# AT32F437 register map
Vendor: Keil; Series: AT32F437; File version: 1.0
CPU: CM4 r0p1, little endian, no MPU, FPU, 4 interrupt priority bits
Registers are 32-bit, read-write, reset 0x0 unless marked. A register's access mark holds for its fields unless they carry their own. Offsets are from the block's base; [hi:lo] are bit positions.

## SPI1 — Serial peripheral interface
Base 0x40013000
Same registers: SPI2 0x40003800, SPI3 0x40003C00, SPI4 0x40013400, I2S2_EXT 0x40017800, I2S3_EXT 0x40017C00
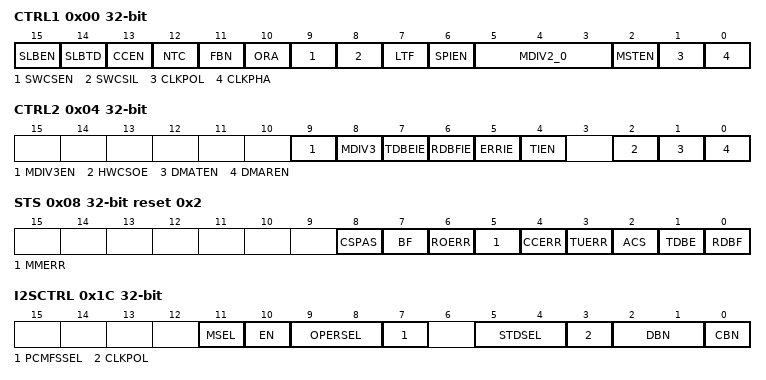
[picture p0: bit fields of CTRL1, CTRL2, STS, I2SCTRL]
0x00 CTRL1 — control register 1
  [15] SLBEN — Single line bidirectional half-duplex enable
    on read: 0=Disabled (Single line bidirectional half-duplex is disabled); 1=Enabled (Single line bidirectional half-duplex is enabled) | on write: 0=Disable (Single line bidirectional half-duplex disable); 1=Enable (Single line bidirectional half-duplex enable)
  [14] SLBTD — Single line bidirectional half-duplex transmission direction
    0=Receive-only mode; 1=Transmit-only mode
  [13] CCEN — CRC calculation enable
    on read: 0=Disabled (CRC calculation is disabled); 1=Enabled (CRC calculation is enabled) | on write: 0=Disable (CRC calculation disable); 1=Enable (CRC calculation enable)
  [12] NTC — Next transmission CRC
    0=Normal (Next transmitted data is the normal value); 1=CRC (Next transmitted data is CRC value)
  [11] FBN — frame bit num
    0=bit8 (8-bit data frame); 1=bit16 (16-bit data frame)
  [10] ORA — Only receive active
    0=RxTx (Transmission and reception); 1=Receive-only mode
  [9] SWCSEN — Software CS enable
    on read: 0=Disabled (Software CS is disabled); 1=Enabled (Software CS is enabled) | on write: 0=Disable (Software CS disable); 1=Enable (Software CS enable)
  [8] SWCSIL — Software CS internal level
    0=Low (Low level); 1=High level
  [7] LTF — LSB transmit first
    0=MSB (Most significant bit first); 1=LSB (Least significant bit first)
  [6] SPIEN — SPI enable
    on read: 0=Disabled (SPI is disabled); 1=Enabled (SPI is enabled) | on write: 0=Disable (SPI disable); 1=Enable (SPI enable)
  [5:3] MDIV2_0 — MDIV[2:0] — master clock frequency division bits 2-0. Combined with MDIV3 (in CTRL2) to form MDIV[3:0]. 0: Divided by 2, 1: Divided by 4, 2: Divided by 8, 3: Divided by 16, 4: Divided by 32, 5: Divided by 64, 6: Divided by 128, 7: Divided by 256, 8: Divided by 512, 9: Divided by 1024
  [2] MSTEN — Master enable
    0=Slave (Master is disabled (Slave)"); 1=Master is enabled"
  [1] CLKPOL — Clock polarity
    0=Low (Low level); 1=High level
  [0] CLKPHA — Clock phase
    0=First (Data capture starts from the first clock edge); 1=Second (Data capture starts from the second clock edge)
0x04 CTRL2 — control register 2
  [9] MDIV3EN — Master clock frequency3 division enable
    0=Disabled; 1=Enabled. MDIV is ignored and SPI clock set to PCLK/3
  [8] MDIV3 — MDIV[3] — master clock frequency division bit 3. Combined with MDIV2_0 (in CTRL1) to form MDIV[3:0]. 0: Divided by 2, 1: Divided by 4, 2: Divided by 8, 3: Divided by 16, 4: Divided by 32, 5: Divided by 64, 6: Divided by 128, 7: Divided by 256, 8: Divided by 512, 9: Divided by 1024
  [7] TDBEIE — Transmit data buffer empty interrupt enable
    on read: 0=Disabled (Transmit data buffer empty interrupt is disabled); 1=Enabled (Transmit data buffer empty interrupt is enabled) | on write: 0=Disable (Transmit data buffer empty interrupt disable); 1=Enable (Transmit data buffer empty interrupt enable)
  [6] RDBFIE — Receive data buffer full interrupt enable
    on read: 0=Disabled (Receive data buffer full interrupt is disabled); 1=Enabled (Receive data buffer full interrupt is enabled) | on write: 0=Disable (Receive data buffer full interrupt disable); 1=Enable (Receive data buffer full interrupt enable)
  [5] ERRIE — Error interrupt enable
    on read: 0=Disabled (Error interrupt is disabled); 1=Enabled (Error interrupt is enabled) | on write: 0=Disable (Error interrupt disable); 1=Enable (Error interrupt enable)
  [4] TIEN — TI mode enable
    0=Disabled (TI mode is disabled (Motorola mode)); 1=Enabled (TI mode is enabled (TI mode))
  [2] HWCSOE — Hardware CS output enable
    on read: 0=Disabled (Hardware CS output is disabled); 1=Enabled (Hardware CS output is enabled) | on write: 0=Disable (Hardware CS output disable); 1=Enable (Hardware CS output enable)
  [1] DMATEN — DMA transmit enable
    on read: 0=Disabled (DMA transmit is disabled); 1=Enabled (DMA transmit is enabled) | on write: 0=Disable (DMA transmit disable); 1=Enable (DMA transmit enable)
  [0] DMAREN — DMA receive enable
    on read: 0=Disabled (DMA receive is disabled); 1=Enabled (DMA receive is enabled) | on write: 0=Disable (DMA receive disable); 1=Enable (DMA receive enable)
0x08 STS reset 0x2 — status register
  [8] CSPAS ro — CS pulse abnormal setting flag
    0=Normal (CS pulse flag normal); 1=Abnormal (CS pulse flag is set abnormally)
  [7] BF ro — Busy flag
    0=Idle (SPI is not busy); 1=Busy (SPI is busy)
  [6] ROERR ro — Receiver overflow error
    0=NoError (No overflow error); 1=Overflow error occurs
  [5] MMERR ro — Master mode error
    0=NoError (No mode error); 1=Error (Mode error occurs)
  [4] CCERR write-0-clears — CRC calculation error
    on read: 0=NoError (No CRC error); 1=Error (CRC error occurs) | on write: 0=Clear CRC error
  [3] TUERR ro — Transmitter underload error
    0=NoError (No underload error); 1=Underload error occurs
  [2] ACS ro — Audio channel state
    0=Left channel; 1=Right channel
  [1] TDBE ro — Transmit data buffer empty
    0=NotEmpty (Transmit data buffer is not empty); 1=Empty (Transmit data buffer is empty)
  [0] RDBF ro — Receive data buffer full
    0=NotFull (Receive data buffer is not full); 1=Full (Receive data buffer is full)
0x0C DT — data register
  [15:0] DT — Data value
0x10 CPOLY reset 0x7 — CRC polynomial register
  [15:0] CPOLY — CRC polynomial
0x14 RCRC ro — Receive CRC register
  [15:0] RCRC — Receive CRC
0x18 TCRC ro — Transmit CRC register
  [15:0] TCRC — Transmit CRC
0x1C I2SCTRL — I2S control register
  [11] MSEL — I2S mode select
    0=SPI (SPI mode); 1=I2S (I2S mode)
  [10] EN — I2S Enable
    on read: 0=Disabled (I2S is disabled); 1=Enabled (I2S is enabled) | on write: 0=Disable (I2S disable); 1=Enable (I2S enable)
  [9:8] OPERSEL — I2S operation select
    0=SlaveTrasmission (Slave transmission); 1=SlaveReception; 2=MasterTrasmission (Master transmission); 3=MasterReception
  [7] PCMFSSEL — PCM frame synchronization select
    0=Short frame synchronization; 1=Long frame synchronization
  [5:4] STDSEL — I2S standard select
    0=Philips standard; 1=MSB (MSB-aligned standard (left-aligned)); 2=LSB (LSB-aligned standard (right-aligned)); 3=PCM (PCM standard)
  [3] CLKPOL — I2S clock polarity
    0=Low; 1=High
  [2:1] DBN — I2S data bit num
    0=bit16 (16-bit wide); 1=bit24 (24-bit wide); 2=bit32 (32-bit wide)
  [0] CBN — I2S channel bit num
    0=bit16 (16-bit wide); 1=bit32 (32-bit wide)
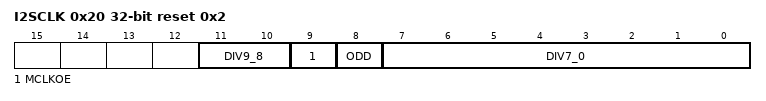
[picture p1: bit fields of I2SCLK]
0x20 I2SCLK reset 0x2 — I2S clock register
  [11:10] DIV9_8 — I2SDIV[9:8] — I2S linear divider high bits. Combined with DIV7_0 to form I2SDIV[9:0]. Actual divider = I2SDIV * 2 (+1 if ODD=1). Values 0 and 0x3FF are not allowed.
  [9] MCLKOE — I2S master clock output enable
    on read: 0=Disabled (Master clock output is disabled); 1=Enabled (Master clock output is enabled) | on write: 0=Disable (Master clock output disable); 1=Enable (Master clock output enable)
  [8] ODD — Odd result for I2S division
    0=Even (Actual divider = I2SDIV * 2); 1=Odd (Actual divider = I2SDIV * 2 + 1)
  [7:0] DIV7_0 — I2SDIV[7:0] — I2S linear divider low bits. Combined with DIV9_8 to form I2SDIV[9:0]. Actual divider = I2SDIV * 2 (+1 if ODD=1). Values 0 and 0x3FF are not allowed.
